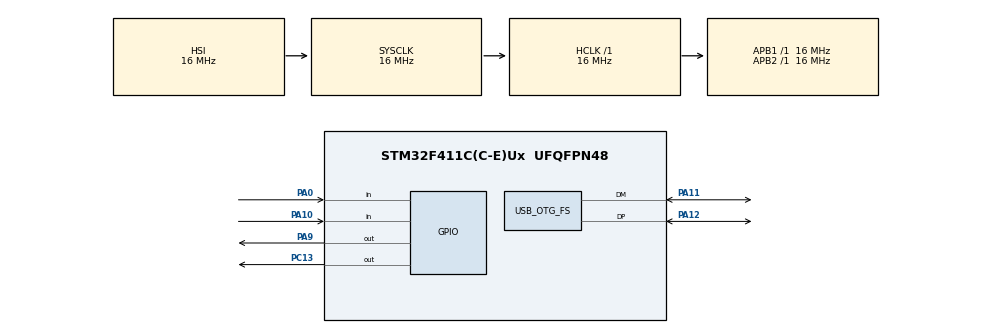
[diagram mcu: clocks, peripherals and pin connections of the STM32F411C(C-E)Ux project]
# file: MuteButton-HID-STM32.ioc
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Mcu.Family=STM32F4
Mcu.Name=STM32F411C(C-E)Ux
Mcu.Package=UFQFPN48
NVIC.OTG_FS_IRQn=true\:0\:0\:false\:false\:true\:false\:true\:true
NVIC.PriorityGroup=NVIC_PRIORITYGROUP_4
NVIC.TIM2_IRQn=true\:15\:0\:false\:false\:true\:false\:true\:true
NVIC.TimeBase=TIM2_IRQn
NVIC.TimeBaseIP=TIM2
PA0-WKUP.Signal=GPIO_Input
PA10.Signal=GPIO_Input
PA11.Mode=Device_Only
PA11.Signal=USB_OTG_FS_DM
PA12.Mode=Device_Only
PA12.Signal=USB_OTG_FS_DP
PA9.Signal=GPIO_Output
PC13-ANTI_TAMP.Signal=GPIO_Output
ProjectManager.HeapSize=0x200
ProjectManager.StackSize=0x400
ProjectManager.TargetToolchain=STM32CubeIDE
RCC.AHBFreq_Value=16000000
RCC.APB1Freq_Value=16000000
RCC.APB2Freq_Value=16000000
RCC.CortexFreq_Value=16000000
RCC.HSE_VALUE=25000000
RCC.HSI_VALUE=16000000
RCC.LSE_VALUE=32768
RCC.PLLSource=RCC_PLLSOURCE_HSI
RCC.SYSCLKFreq_VALUE=16000000
RCC.VCOOutputFreq_Value=192000000
USB_DEVICE.CLASS_NAME_FS=CUSTOM_HID
USB_DEVICE.CUSTOM_HID_FS_BINTERVAL=0x1
USB_DEVICE.USBD_CUSTOMHID_OUTREPORT_BUF_SIZE=64
USB_DEVICE.USBD_CUSTOM_HID_REPORT_DESC_SIZE=32
USB_DEVICE.VirtualMode=CustomHid
USB_DEVICE.VirtualModeFS=Custom_Hid_FS
USB_OTG_FS.VirtualMode=Device_Only
VP_SYS_VS_tim2.Mode=TIM2
VP_USB_DEVICE_VS_USB_DEVICE_CUSTOM_HID_FS.Mode=CUSTOM_HID_FS
board=custom

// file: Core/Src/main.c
/* USER CODE BEGIN Header */
/**
  ******************************************************************************
  * @file           : main.c
  * @brief          : Main program body
  ******************************************************************************
  * @attention
  *
  * Copyright (c) 2023 STMicroelectronics.
  * All rights reserved.
  *
  * This software is licensed under terms that can be found in the LICENSE file
  * in the root directory of this software component.
  * If no LICENSE file comes with this software, it is provided AS-IS.
  *
  ******************************************************************************
  */
/* USER CODE END Header */
#include "main.h"
#include "usb_device.h"

void SystemClock_Config(void);
static void MX_GPIO_Init(void);

int main(void)
{

  /* MCU Configuration--------------------------------------------------------*/

  /* Reset of all peripherals, Initializes the Flash interface and the Systick. */
  HAL_Init();

  /* Configure the system clock */
  SystemClock_Config();

  /* Initialize all configured peripherals */
  MX_GPIO_Init();
  MX_USB_DEVICE_Init();

  /* Infinite loop */
  /* USER CODE BEGIN WHILE */
  uint8_t res[USBD_CUSTOMHID_OUTREPORT_BUF_SIZE] = { 0x44,0x55};
  while (1)
  {
    /* USER CODE END WHILE */

    /* USER CODE BEGIN 3 */
	  //if(HAL_GPIO_ReadPin(GPIOA, GPIO_PIN_0) || HAL_GPIO_ReadPin(GPIOA, GPIO_PIN_10){
	  	  if(HAL_GPIO_ReadPin(GPIOA, GPIO_PIN_10)){
	  		  res[0] = 'S';
	  		  USBD_CUSTOM_HID_SendReport_FS(res,USBD_CUSTOMHID_OUTREPORT_BUF_SIZE);
	  	  }else{
	  		  res[0] = 'M';
	  		  USBD_CUSTOM_HID_SendReport_FS(res,USBD_CUSTOMHID_OUTREPORT_BUF_SIZE);
	  	  }
	  	  for(int i = 0;i < 10000;i++);
  }
  /* USER CODE END 3 */
}

void SystemClock_Config(void)
{
  RCC_OscInitTypeDef RCC_OscInitStruct = {0};
  RCC_ClkInitTypeDef RCC_ClkInitStruct = {0};

  /** Configure the main internal regulator output voltage
  */
  __HAL_RCC_PWR_CLK_ENABLE();
  __HAL_PWR_VOLTAGESCALING_CONFIG(PWR_REGULATOR_VOLTAGE_SCALE1);

  /** Initializes the RCC Oscillators according to the specified parameters
  * in the RCC_OscInitTypeDef structure.
  */
  RCC_OscInitStruct.OscillatorType = RCC_OSCILLATORTYPE_HSI;
  RCC_OscInitStruct.HSIState = RCC_HSI_ON;
  RCC_OscInitStruct.HSICalibrationValue = RCC_HSICALIBRATION_DEFAULT;
  RCC_OscInitStruct.PLL.PLLState = RCC_PLL_ON;
  RCC_OscInitStruct.PLL.PLLSource = RCC_PLLSOURCE_HSI;
  RCC_OscInitStruct.PLL.PLLM = 16;
  RCC_OscInitStruct.PLL.PLLN = 192;
  RCC_OscInitStruct.PLL.PLLP = RCC_PLLP_DIV2;
  RCC_OscInitStruct.PLL.PLLQ = 4;
  if (HAL_RCC_OscConfig(&RCC_OscInitStruct) != HAL_OK)
  {
    Error_Handler();
  }

  /** Initializes the CPU, AHB and APB buses clocks
  */
  RCC_ClkInitStruct.ClockType = RCC_CLOCKTYPE_HCLK|RCC_CLOCKTYPE_SYSCLK
                              |RCC_CLOCKTYPE_PCLK1|RCC_CLOCKTYPE_PCLK2;
  RCC_ClkInitStruct.SYSCLKSource = RCC_SYSCLKSOURCE_HSI;
  RCC_ClkInitStruct.AHBCLKDivider = RCC_SYSCLK_DIV1;
  RCC_ClkInitStruct.APB1CLKDivider = RCC_HCLK_DIV1;
  RCC_ClkInitStruct.APB2CLKDivider = RCC_HCLK_DIV1;

  if (HAL_RCC_ClockConfig(&RCC_ClkInitStruct, FLASH_LATENCY_0) != HAL_OK)
  {
    Error_Handler();
  }
}

static void MX_GPIO_Init(void)
{
  GPIO_InitTypeDef GPIO_InitStruct = {0};

  /* GPIO Ports Clock Enable */
  __HAL_RCC_GPIOC_CLK_ENABLE();
  __HAL_RCC_GPIOA_CLK_ENABLE();

  /*Configure GPIO pin Output Level */
  HAL_GPIO_WritePin(GPIOC, GPIO_PIN_13, GPIO_PIN_RESET);

  /*Configure GPIO pin Output Level */
  HAL_GPIO_WritePin(GPIOA, GPIO_PIN_9, GPIO_PIN_RESET);

  /*Configure GPIO pin : PC13 */
  GPIO_InitStruct.Pin = GPIO_PIN_13;
  GPIO_InitStruct.Mode = GPIO_MODE_OUTPUT_PP;
  GPIO_InitStruct.Pull = GPIO_NOPULL;
  GPIO_InitStruct.Speed = GPIO_SPEED_FREQ_LOW;
  HAL_GPIO_Init(GPIOC, &GPIO_InitStruct);

  /*Configure GPIO pins : PA0 PA10 */
  GPIO_InitStruct.Pin = GPIO_PIN_0|GPIO_PIN_10;
  GPIO_InitStruct.Mode = GPIO_MODE_INPUT;
  GPIO_InitStruct.Pull = GPIO_NOPULL;
  HAL_GPIO_Init(GPIOA, &GPIO_InitStruct);

  /*Configure GPIO pin : PA9 */
  GPIO_InitStruct.Pin = GPIO_PIN_9;
  GPIO_InitStruct.Mode = GPIO_MODE_OUTPUT_PP;
  GPIO_InitStruct.Pull = GPIO_NOPULL;
  GPIO_InitStruct.Speed = GPIO_SPEED_FREQ_LOW;
  HAL_GPIO_Init(GPIOA, &GPIO_InitStruct);

}

void HAL_TIM_PeriodElapsedCallback(TIM_HandleTypeDef *htim)
{
  if (htim->Instance == TIM2) {
    HAL_IncTick();
  }
}

void Error_Handler(void)
{
  __disable_irq();
  while (1)
  {
  }
}
